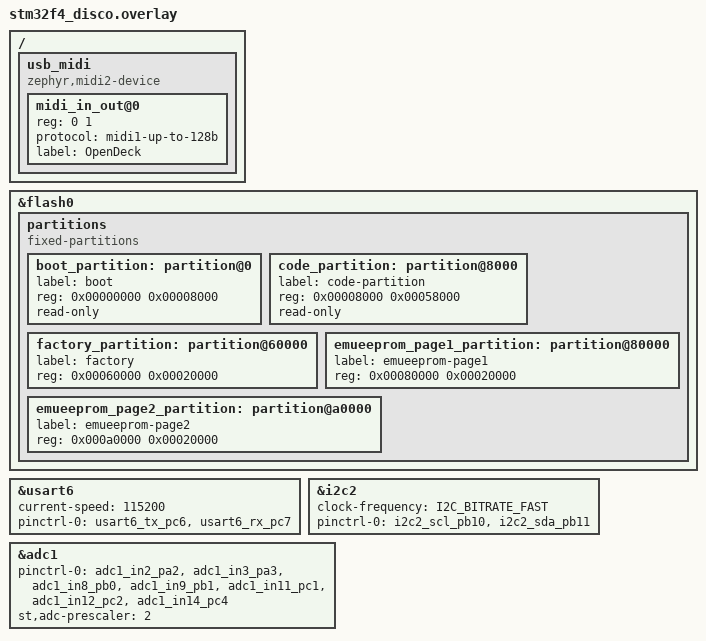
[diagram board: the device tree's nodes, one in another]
/ {
    usb_midi: usb_midi {
        compatible = "zephyr,midi2-device";
        status = "okay";
        #address-cells = <1>;
        #size-cells = <1>;

        midi_in_out@0 {
            reg = <0 1>;
            protocol = "midi1-up-to-128b";
            label = "OpenDeck";
        };
    };
};

&flash0 {
    partitions {
        compatible = "fixed-partitions";
        #address-cells = <1>;
        #size-cells = <1>;

        boot_partition: partition@0 {
            label = "boot";
            reg = <0x00000000 0x00008000>;
            read-only;
        };

        code_partition: partition@8000 {
            label = "code-partition";
            reg = <0x00008000 0x00058000>;
            read-only;
        };

        factory_partition: partition@60000 {
            label = "factory";
            reg = <0x00060000 0x00020000>;
        };

        emueeprom_page1_partition: partition@80000 {
            label = "emueeprom-page1";
            reg = <0x00080000 0x00020000>;
        };

        emueeprom_page2_partition: partition@a0000 {
            label = "emueeprom-page2";
            reg = <0x000a0000 0x00020000>;
        };
    };
};

&usart6 {
    current-speed = <115200>;
    pinctrl-0 = <&usart6_tx_pc6 &usart6_rx_pc7>;
    pinctrl-names = "default";
    status = "okay";
};

&i2c2 {
    clock-frequency = <I2C_BITRATE_FAST>;
    pinctrl-0 = <&i2c2_scl_pb10 &i2c2_sda_pb11>;
    pinctrl-names = "default";
    status = "okay";
};

&adc1 {
    pinctrl-0 = <&adc1_in2_pa2
                 &adc1_in3_pa3
                 &adc1_in8_pb0
                 &adc1_in9_pb1
                 &adc1_in11_pc1
                 &adc1_in12_pc2
                 &adc1_in14_pc4>;
    pinctrl-names = "default";
    st,adc-prescaler = <2>;
    status = "okay";
};
